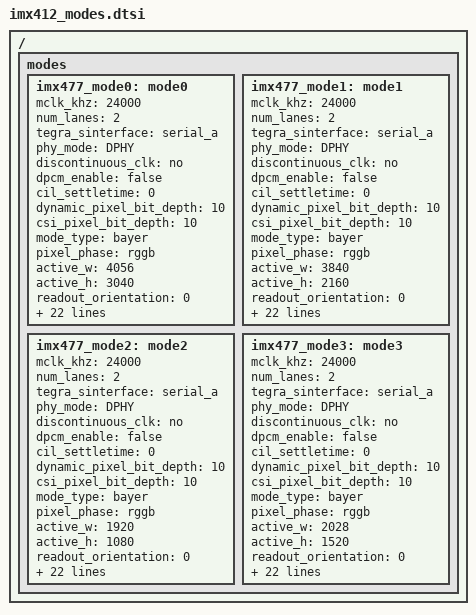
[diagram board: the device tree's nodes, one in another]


/ {
    modes {
        imx477_mode0: mode0 {
            mclk_khz = "24000";
            num_lanes = "2";
            tegra_sinterface = "serial_a";
            phy_mode = "DPHY";
            discontinuous_clk = "no";
            dpcm_enable = "false";
            cil_settletime = "0";
            dynamic_pixel_bit_depth = "10";
            csi_pixel_bit_depth = "10";
            mode_type = "bayer";
            pixel_phase = "rggb";

            active_w = "4056";
            active_h = "3040";
            readout_orientation = "0";
            line_length = "9024";
            inherent_gain = "1";
            mclk_multiplier = "18";
            pix_clk_hz = "419200000";

            gain_factor = "16";
            framerate_factor = "1000000";
            exposure_factor = "1000000";
            min_gain_val = "16"; /* 1.00x */
            max_gain_val = "256"; /* 16x */
            step_gain_val = "1";
            default_gain = "16"; /* 1.00x */
            min_hdr_ratio = "1";
            max_hdr_ratio = "1";
            min_framerate = "1000000"; /* 2.0 fps */
            max_framerate = "30000000"; /* 30.0 fps */
            step_framerate = "1";
            default_framerate = "30000000"; /* 30.0 fps */
            min_exp_time = "16"; /* us */
            max_exp_time = "16666"; /* us */
            step_exp_time = "1";
            default_exp_time = "16666"; /* us */
            embedded_metadata_height = "2";
        };
        imx477_mode1: mode1 {
            mclk_khz = "24000";
            num_lanes = "2";
            tegra_sinterface = "serial_a";
            phy_mode = "DPHY";
            discontinuous_clk = "no";
            dpcm_enable = "false";
            cil_settletime = "0";
            dynamic_pixel_bit_depth = "10";
            csi_pixel_bit_depth = "10";
            mode_type = "bayer";
            pixel_phase = "rggb";

            active_w = "3840";
            active_h = "2160";
            readout_orientation = "0";
            line_length = "11200";
            inherent_gain = "1";
            mclk_multiplier = "80";
            pix_clk_hz = "300000000";

            gain_factor = "16";
            framerate_factor = "1000000";
            exposure_factor = "1000000";
            min_gain_val = "16"; /* 1.00x */
            max_gain_val = "356"; /* 22x */
            step_gain_val = "1";
            default_gain = "16"; /* 1.00x */
            min_hdr_ratio = "1";
            max_hdr_ratio = "1";
            min_framerate = "2000000"; /* 2.0 fps */
            max_framerate = "30000000"; /* 30.0 fps */
            step_framerate = "1";
            default_framerate = "30000000"; /* 30.0 fps */
            min_exp_time = "13"; /* us */
            max_exp_time = "683709"; /* us */
            step_exp_time = "1";
            default_exp_time = "2495"; /* us */

            embedded_metadata_height = "2";
        };
        imx477_mode2: mode2 {
            mclk_khz = "24000";
            num_lanes = "2";
            tegra_sinterface = "serial_a";
            phy_mode = "DPHY";
            discontinuous_clk = "no";
            dpcm_enable = "false";
            cil_settletime = "0";
            dynamic_pixel_bit_depth = "10";
            csi_pixel_bit_depth = "10";
            mode_type = "bayer";
            pixel_phase = "rggb";

            active_w = "1920";
            active_h = "1080";
            readout_orientation = "0";
            line_length = "7000";
            inherent_gain = "1";
            mclk_multiplier = "80";
            pix_clk_hz = "300000000";

            gain_factor = "16";
            framerate_factor = "1000000";
            exposure_factor = "1000000";
            min_gain_val = "16"; /* 1.00x */
            max_gain_val = "356"; /* 22x */
            step_gain_val = "1";
            default_gain = "16"; /* 1.00x */
            min_hdr_ratio = "1";
            max_hdr_ratio = "1";
            min_framerate = "2000000"; /* 2.0 fps */
            max_framerate = "60000000"; /* 60.0 fps */
            step_framerate = "1";
            default_framerate = "60000000"; /* 60.0 fps */
            min_exp_time = "13"; /* us */
            max_exp_time = "683709"; /* us */
            step_exp_time = "1";
            default_exp_time = "2495"; /* us */

            embedded_metadata_height = "2";
        };
        imx477_mode3: mode3 {
            mclk_khz = "24000";
            num_lanes = "2";
            tegra_sinterface = "serial_a";
            phy_mode = "DPHY";
            discontinuous_clk = "no";
            dpcm_enable = "false";
            cil_settletime = "0";
            dynamic_pixel_bit_depth = "10";
            csi_pixel_bit_depth = "10";
            mode_type = "bayer";
            pixel_phase = "rggb";

            active_w = "2028";
            active_h = "1520";
            readout_orientation = "0";
            line_length = "7000";
            inherent_gain = "1";
            mclk_multiplier = "18";
            pix_clk_hz = "300000000";

            gain_factor = "16";
            framerate_factor = "1000000";
            exposure_factor = "1000000";
            min_gain_val = "16"; /* 1.00x */
            max_gain_val = "256"; /* 16x */
            step_gain_val = "1";
            default_gain = "16"; /* 1.00x */
            min_hdr_ratio = "1";
            max_hdr_ratio = "1";
            min_framerate = "1000000"; /* 2.0 fps */
            max_framerate = "27000000"; /* 120.0 fps */
            step_framerate = "1";
            default_framerate = "27000000"; /* 60.0 fps */
            min_exp_time = "16"; /* us */
            max_exp_time = "16666"; /* us */
            step_exp_time = "1";
            default_exp_time = "16666"; /* us */
            embedded_metadata_height = "2";
        };
    };
};
